# pse84_a0 register map
Vendor: Infineon Technologies; Series: PSE84_A0; File version: 1.0
CPU: CM33 r0p1, little endian, MPU, FPU, VTOR, 3 interrupt priority bits
Registers are 32-bit, read-write, reset 0x0 unless marked. A register's access mark holds for its fields unless they carry their own. Offsets are from the block's base; [hi:lo] are bit positions; lines under a group give offsets from that group; {n}, {i} and the like mark numbered series.

## SAXI_DMAC — AXI DMAC
Base 0x441A0000
0x00 CTL — Control
  [31] ENABLED — IP enable: '0': Disabled. Clearing this field to '0' by software shuts down all channels by clearing their CH_CTL.ENABLED fields, unless all CH_STATUS.ENABLED fields are '0'. After all channels have completed their AXI transactions, all non-retention registers (command and status registers) are reset to their default value, and all retention registers retain their value. '1': Enabled.
    0=DISABLED (N/A); 1=ENABLED (N/A)
0x04 STATUS ro — Enabled channels
  [7:0] CH_EN — Specifies channels whose CH_STATUS.ENABLED = '1', i.e. channels that are either enabled, or are still completing their AXI transactions after being disabled.
0x08 ACTIVE ro — Active channels
  [7:0] ACTIVE — Specifies active channels; i.e. enabled channels whose trigger got activated.
{0x1000+0x100*i} CH[{i}] (i=0..3) group — AXI DMA controller channel
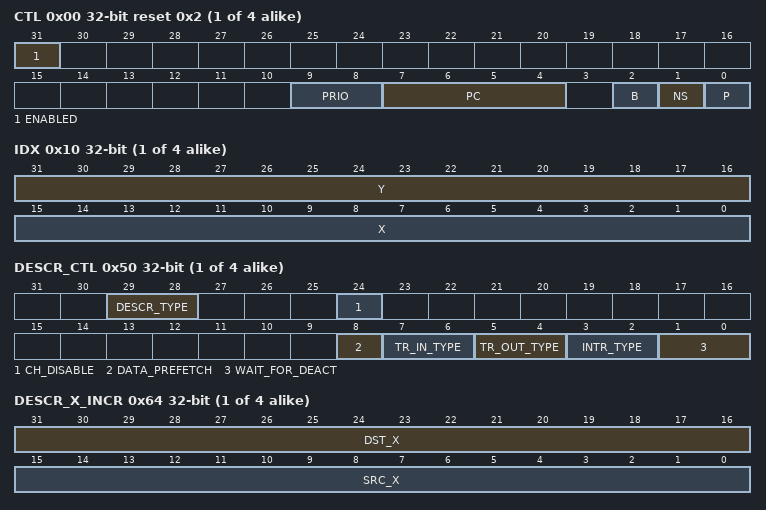
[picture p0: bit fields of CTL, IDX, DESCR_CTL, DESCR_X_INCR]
  0x00 CTL reset 0x2 — Channel control
    [31] ENABLED — Channel enable: '0': Disabled. The channel's trigger is ignored and the channel cannot be made active. If an active channel is disabled, the channel is de-activated: This field is set to '0' immediately, and CH_STATUS.ENABLED is set to '0' by HW after AXI bus transactions are completed. '1': Enabled. SW sets this field to '1' to enable a specific channel. HW sets this field to '0' in the following cases: - when an error interrupt cause is activated - when a descriptor has completed, if CH_DESCR_CTL.CH_DISABLE is '1' - when CTL.ENABLED is cleared to '0' by SW while the CH_STATUS.ENABLED field of at least one channel is '1'
    [9:8] PRIO — Channel priority: '0': highest priority. '1' '2' '3': lowest priority. Channels with the same priority constitute a priority group. Priority decoding determines the highest priority pending channel. This channel is determined as follows. First, the highest priority group with pending channels is identified. Second, within this priority group, roundrobin arbitration is applied. Roundrobin arbitration (within a priority group) gives the highest priority to the lower channel indices (within the priority group).
    [7:4] PC — Protection Context This field can only be updated based on software write to this register. However, value of this field is set with the protection context of the transaction that writes this register; i.e. the 'write data' is ignored and instead the context is inherited from the write transaction All transactions for this channel uses the PC field for the protection context. Note: This is an exception as compared to other Registers, where the field value is inherited from the bus, instead of 'write data'.
    [2] B — Non-bufferable/bufferable access control: '0': non-bufferable. '1': bufferable. This field is used to indicate to an AMBA bridge that a write transaction can complete without waiting for the destination to accept the write transaction data. All transactions for this channel uses the B field for the non-bufferable/bufferable access control ('acache[0]').
    [1] NS — Secure/on-secure access control: '0': secure. '1': non-secure. This field can only be updated based on software write to this register. However, value of this field is set with the secure/non-secure access control of the transaction that writes this register; i.e. the 'write data' is ignored and instead the access control is inherited from the write transaction ('hnonsec') All transactions for this channel use the NS field for the secure/non-secure access control ('aprot[1]'). Note: This is an exception as compared to other registers, where the field value is inherited from the bus, instead of 'write data'.
    [0] P — User/privileged access control: '0': user mode. '1': privileged mode. This field can only be updated based on software write to this register. However, value of this field is set with the user/privileged access control of the transaction that writes this register; i.e. the 'write data' is ignored and instead the access control is inherited from the write transaction ('hprot[1]') All transactions for this channel use the P field for the user/privileged access control ('aprot[0]'). Note: This is an exception as compared to other registers, where the field value is inherited from the bus, instead of 'write data'.
  0x04 STATUS ro — Channel status
    [31] ENABLED — Indicates the enable status of the channel. '0': Disabled. '1': Enabled. When CH_CTL.ENABLED is set to '0' by SW or by the activation of an error interrupt cause or by disabling the entire DMAC, HW sets this field to '0' after the channel has completed AXI transactions. When SW sets CH_CTL.ENABLED to '1' and this field is '0', it changes from '0' to '1' immediately (if the entire DMAC is still disabled by CTL.ENABLED, it changes from '0' to '1' after the DMAC gets enabled). If this field is '1' at the time CH_CTL_ENABLED is changed from '0' to '1', then this field is first set to '0' by HW after the channel has completed AXI transactions, and it is set to '1' after one clock cycle if CH_CTL.ENABLED is still '1'. This ensures that the channel is properly initialized (except the retained registers).
  0x10 IDX ro reset not defined — Channel current X and Y indices
    [31:16] Y — Specifies the Y loop index. In the range of [0, Y_COUNT], with Y_COUNT taken from the current descriptor. Note: HW sets this field to '0' when it loads a descriptor..
    [15:0] X — Specifies the X loop index. In the range of [0, X_COUNT], with X_COUNT taken from the current descriptor. Note: HW sets this field to '0' when it loads a descriptor.
  0x14 SRC ro reset not defined — Channel current source address
    [31:0] ADDR — Current address of source location.
  0x18 DST ro reset not defined — Channel current destination address
    [31:0] ADDR — Current address of destination location.
  0x1C M_IDX ro reset not defined — Channel current M index
    [23:0] M — Specifies the M loop index. In the range of [0, M_COUNT], with M_COUNT taken from the current descriptor. Note: HW sets this field to '0' when it loads a descriptor.
  0x20 CURR reset not defined — Channel current descriptor pointer
    [31:3] PTR — Address of current descriptor. When this field is '0', there is no valid descriptor. Note: HW updates the current descriptor pointer CH_CURR_PTR with DESCR_NEXT_PTR after execution of the current descriptor. Note: When this field is '0', and the DMAC and the channel are enabled, and the channel is triggered, then this will raise the CURR_PTR_NULL interrupt, and initiate the disabling of the channel. If this field is changed to a value different from '0' afterwards, then the channel may start to fetch the descriptor before finally being disabled, and the ISR will find this field not being '0' although the CURR_PTR_NULL interrupt has been raised.
  0x28 TR_CMD — Channel software trigger
    [0] ACTIVATE — Software trigger. When written with '1', a trigger is generated which sets 'trigger pending' (only if the channel is enabled). A read always returns a 0.
  0x40 DESCR_STATUS ro — Channel descriptor status
    [31] VALID — Indicates whether the descriptor information present in DESCR_CTL, DESCR_SRC, DESCR_DST, DESCR_M_SIZE, DESCR_X_SIZE, DESCR_X_INCR, DESCR_Y_SIZE, DESCR_Y_INCR, DESCR_NEXT status registers is valid or not. 0: Valid 1: Not Valid
  0x50 DESCR_CTL ro reset not defined — Channel descriptor control
    [29:28] DESCR_TYPE, [24] CH_DISABLE, [8] DATA_PREFETCH, [7:6] TR_IN_TYPE, [5:4] TR_OUT_TYPE, [3:2] INTR_TYPE, [1:0] WAIT_FOR_DEACT
  0x54 DESCR_SRC ro reset not defined — Channel descriptor source
    [31:0] ADDR
  0x58 DESCR_DST ro reset not defined — Channel descriptor destination
    [31:0] ADDR
  0x5C DESCR_M_SIZE ro reset not defined — Channel descriptor M size
    [23:0] M_COUNT
  0x60 DESCR_X_SIZE ro reset not defined — Channel descriptor X size
    [15:0] X_COUNT
  0x64 DESCR_X_INCR ro reset not defined — Channel descriptor X increment
    [31:16] DST_X, [15:0] SRC_X
  0x68 DESCR_Y_SIZE ro reset not defined — Channel descriptor Y size
    [15:0] Y_COUNT
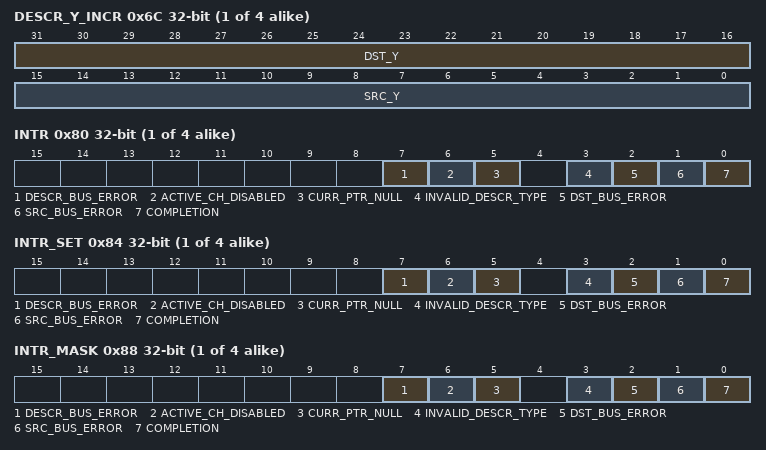
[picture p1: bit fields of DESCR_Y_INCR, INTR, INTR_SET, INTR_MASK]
  0x6C DESCR_Y_INCR ro reset not defined — Channel descriptor Y increment
    [31:16] DST_Y, [15:0] SRC_Y
  0x70 DESCR_NEXT ro reset not defined — Channel descriptor next pointer
    [31:3] PTR
  0x80 INTR — Interrupt
    [7] DESCR_BUS_ERROR — Activated (set to '1') on a bus error for a load of the descriptor.
    [6] ACTIVE_CH_DISABLED — Activated (set to '1') when the channel is disabled and the data transfer engine is busy, i.e there is a pending trigger. This flag is also set if an input trigger is received at the same time another error occurs (in this case, ACT_CH_DISABLED is set in addition to another error interrupt flag).
    [5] CURR_PTR_NULL — Activated (set to '1') when the channel is enabled (CH_CTL.ENABLED is '1'), CH_CURR_PTR is '0', and the channel is triggered.
    [3] INVALID_DESCR_TYPE — Activated (set to '1') when the descriptor type is invalid.
    [2] DST_BUS_ERROR — Activated (set to '1') on a bus error for a store to the destination. Also activated when an AXI write response is received although there is no outstanding write transaction.
    [1] SRC_BUS_ERROR — Activated (set to '1') on a bus error for a load from the source. Note that INTR.COMPLETION is not valid if it is activated along with INTR.SRC_BUS_ERROR. When INTR.SRC_BUS_ERROR status is activated, then destination data may be corrupted.
    [0] COMPLETION — Activated (set to '1') on completion of data transfer(s) as specified by the descriptor's CH_DESCR_CTL.INTR_TYPE. Note that this flag is not valid if it is activated along with INTR.SRC_BUS_ERROR. In this case destination data corresponding to this completion flag may be corrupted.
  0x84 INTR_SET — Interrupt set
    [7] DESCR_BUS_ERROR
    [6] ACTIVE_CH_DISABLED
    [5] CURR_PTR_NULL
    [3] INVALID_DESCR_TYPE
    [2] DST_BUS_ERROR
    [1] SRC_BUS_ERROR
    [0] COMPLETION — Write this field with '1' to set corresponding INTR field to '1' (a write of '0' has no effect).
  0x88 INTR_MASK — Interrupt mask
    [7] DESCR_BUS_ERROR
    [6] ACTIVE_CH_DISABLED
    [5] CURR_PTR_NULL
    [3] INVALID_DESCR_TYPE
    [2] DST_BUS_ERROR
    [1] SRC_BUS_ERROR
    [0] COMPLETION — Mask for corresponding field in INTR register.
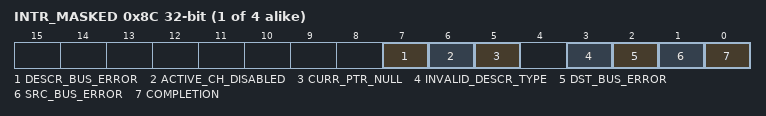
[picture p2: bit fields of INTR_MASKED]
  0x8C INTR_MASKED ro — Interrupt masked
    [7] DESCR_BUS_ERROR
    [6] ACTIVE_CH_DISABLED
    [5] CURR_PTR_NULL
    [3] INVALID_DESCR_TYPE
    [2] DST_BUS_ERROR
    [1] SRC_BUS_ERROR
    [0] COMPLETION — Logical and of corresponding INTR and INTR_MASK fields.
